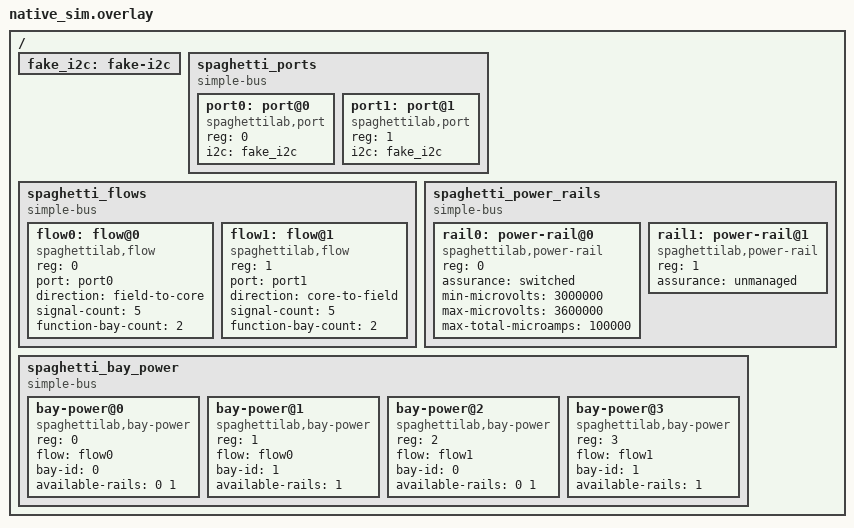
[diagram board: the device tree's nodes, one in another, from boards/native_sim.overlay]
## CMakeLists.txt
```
cmake_minimum_required(VERSION 3.20.0)

list(APPEND DTS_ROOT ${CMAKE_CURRENT_SOURCE_DIR}/../..)

find_package(Zephyr REQUIRED HINTS $ENV{ZEPHYR_BASE})
project(spaghetti_v1_extension_test)

target_sources(app PRIVATE
  src/main.c
  src/harness.c
  src/fake_temperature.c
  src/fake_button.c
  src/fake_pwm.c
  src/fake_rule.c
  src/fake_register_profiles.c
  src/fake_processing_block.c
  src/fake_eeprom_provider.c
  src/fake_analog_provider.c
  ../../subsys/schema/schema.c
  ../../subsys/driver_registry/driver_registry.c
  ../../subsys/rule_registry/rule_registry.c
  ../../subsys/block_registry/block_registry.c
  ../../subsys/device_profiles/device_profile.c
  ../../subsys/device_profiles/device_profile_exec.c
  ../../subsys/module_manager/module_manager.c
  ../../subsys/config/config.c
  ../../subsys/config/config_cbor.c
  ../../subsys/data/data.c
  ../../subsys/data/record_delivery.c
  ../../subsys/processing/processing.c
  ../../subsys/discovery/discovery.c
  ../../subsys/topology/topology.c
  ../../subsys/power/power.c
  ../../subsys/resources/resources_note_weak.c
  ../../spaghetti_modules/declarative_device/declarative_device.c
)

target_include_directories(app PRIVATE
  ../../include
  ../../subsys/driver_registry
  ../../subsys/rule_registry
  ../../subsys/block_registry
  ../../subsys/device_profiles
  ../../subsys/topology
  ../../subsys/power
  ../../subsys/discovery
  ../../spaghetti_modules/declarative_device
  src
)

zephyr_linker_sources(SECTIONS ../../subsys/driver_registry/driver_sections.ld)
zephyr_linker_sources(SECTIONS ../../subsys/rule_registry/rule_sections.ld)
zephyr_linker_sources(SECTIONS ../../subsys/block_registry/block_sections.ld)
zephyr_linker_sources(SECTIONS
  ../../subsys/device_profiles/device_profile_sections.ld)
zephyr_linker_sources(SECTIONS
  ../../subsys/discovery/discovery_sections.ld)
zephyr_linker_sources(SECTIONS
  ../../subsys/data/record_delivery_sections.ld)
zephyr_linker_sources(SECTIONS ../../subsys/core/health_sections.ld)
```

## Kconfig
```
mainmenu "Spaghetti V1 extension proof tests"

rsource "../../Kconfig.resources"

config SPAGHETTI_POWER
	bool
	default y

config SPAGHETTI_POWER_FAKE_BACKEND
	bool
	default y

config SPAGHETTI_POWER_LOG_LEVEL
	int
	default 0

config SPAGHETTI_TOPOLOGY_LOG_LEVEL
	int
	default 0

config SPAGHETTI_DRIVER_REGISTRY_LOG_LEVEL
	int
	default 0

config SPAGHETTI_RULE_REGISTRY_LOG_LEVEL
	int
	default 0

config SPAGHETTI_BLOCK_REGISTRY_LOG_LEVEL
	int
	default 0

config SPAGHETTI_DEVICE_PROFILE_LOG_LEVEL
	int
	default 0

config SPAGHETTI_SCHEMA_LOG_LEVEL
	int
	default 0

config SPAGHETTI_CONFIG_LOG_LEVEL
	int
	default 0

config SPAGHETTI_MODULE_MANAGER_LOG_LEVEL
	int
	default 0

config SPAGHETTI_DATA_LOG_LEVEL
	int
	default 0

config SPAGHETTI_RECORD_DELIVERY_LOG_LEVEL
	int
	default 0

config SPAGHETTI_PROCESSING_LOG_LEVEL
	int
	default 0

config SPAGHETTI_DISCOVERY_LOG_LEVEL
	int
	default 0

config SPAGHETTI_DISCOVERY_MAX_RESULTS
	int
	default 8

config SPAGHETTI_DECLARATIVE_DEVICE_MAX_INSTANCES
	int
	range 1 SPAGHETTI_MAX_MODULES
	default 4

config SPAGHETTI_DECLARATIVE_DEVICE_LOG_LEVEL
	int
	default 0

config SPAGHETTI_RUNTIME_STOP_TIMEOUT_MS
	int
	default 1000

config SPAGHETTI_MQTT_STOP_TIMEOUT_MS
	int
	default 2000

config SPAGHETTI_CONFIG_MIN_WRITE_INTERVAL_MS
	int
	default 0

config ZCBOR
	bool
	default y

source "Kconfig.zephyr"
```

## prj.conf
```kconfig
CONFIG_ZTEST=y
CONFIG_LOG=y
CONFIG_ZCBOR=y
CONFIG_ZBUS=y
CONFIG_ZBUS_MSG_SUBSCRIBER=y
CONFIG_ZBUS_PREFER_DYNAMIC_ALLOCATION=n
CONFIG_ZBUS_MSG_SUBSCRIBER_BUF_ALLOC_STATIC=y
CONFIG_ZBUS_MSG_SUBSCRIBER_NET_BUF_POOL_SIZE=8
CONFIG_ZBUS_MSG_SUBSCRIBER_NET_BUF_STATIC_DATA_SIZE=768
CONFIG_SPAGHETTI_RESOURCE_PROFILE_MINIMAL=y
```

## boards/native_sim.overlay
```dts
/ {
	fake_i2c: fake-i2c {
		status = "okay";
	};

	spaghetti_ports {
		compatible = "simple-bus";
		#address-cells = <1>;
		#size-cells = <0>;

		port0: port@0 {
			compatible = "spaghettilab,port";
			reg = <0>;
			i2c = <&fake_i2c>;
			status = "okay";
		};

		port1: port@1 {
			compatible = "spaghettilab,port";
			reg = <1>;
			i2c = <&fake_i2c>;
			status = "okay";
		};
	};

	spaghetti_flows {
		compatible = "simple-bus";
		#address-cells = <1>;
		#size-cells = <0>;

		flow0: flow@0 {
			compatible = "spaghettilab,flow";
			reg = <0>;
			port = <&port0>;
			direction = "field-to-core";
			signal-count = <5>;
			function-bay-count = <2>;
			status = "okay";
		};

		flow1: flow@1 {
			compatible = "spaghettilab,flow";
			reg = <1>;
			port = <&port1>;
			direction = "core-to-field";
			signal-count = <5>;
			function-bay-count = <2>;
			status = "okay";
		};
	};

	spaghetti_power_rails {
		compatible = "simple-bus";
		#address-cells = <1>;
		#size-cells = <0>;

		rail0: power-rail@0 {
			compatible = "spaghettilab,power-rail";
			reg = <0>;
			assurance = "switched";
			min-microvolts = <3000000>;
			max-microvolts = <3600000>;
			max-total-microamps = <100000>;
			status = "okay";
		};

		rail1: power-rail@1 {
			compatible = "spaghettilab,power-rail";
			reg = <1>;
			assurance = "unmanaged";
			status = "okay";
		};
	};

	spaghetti_bay_power {
		compatible = "simple-bus";
		#address-cells = <1>;
		#size-cells = <0>;

		bay-power@0 {
			compatible = "spaghettilab,bay-power";
			reg = <0>;
			flow = <&flow0>;
			bay-id = <0>;
			available-rails = <0 1>;
			status = "okay";
		};

		bay-power@1 {
			compatible = "spaghettilab,bay-power";
			reg = <1>;
			flow = <&flow0>;
			bay-id = <1>;
			available-rails = <1>;
			status = "okay";
		};

		bay-power@2 {
			compatible = "spaghettilab,bay-power";
			reg = <2>;
			flow = <&flow1>;
			bay-id = <0>;
			available-rails = <0 1>;
			status = "okay";
		};

		bay-power@3 {
			compatible = "spaghettilab,bay-power";
			reg = <3>;
			flow = <&flow1>;
			bay-id = <1>;
			available-rails = <1>;
			status = "okay";
		};
	};
};
```

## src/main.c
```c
/**
 * @file
 * @brief V1 extension proof: fake plug-ins only under tests/v1_extension/.
 *
 * Does not patch driver_registry/, rule_registry/, config/, data/, runtime/,
 * communication/, or services/mqtt/.
 */

#include <errno.h>
#include <stdbool.h>
#include <stdint.h>
#include <string.h>

#include <zephyr/sys/util.h>
#include <zephyr/ztest.h>

#include <spaghetti/block_registry.h>
#include <spaghetti/config.h>
#include <spaghetti/data.h>
#include <spaghetti/device_profile.h>
#include <spaghetti/discovery.h>
#include <spaghetti/driver_registry.h>
#include <spaghetti/module_manager.h>
#include <spaghetti/port.h>
#include <spaghetti/power.h>
#include <spaghetti/processing.h>
#include <spaghetti/record_delivery.h>
#include <spaghetti/rule_registry.h>
#include <spaghetti/schema.h>
#include <spaghetti/topology.h>

#include "harness.h"
#include "topology_internal.h"

int fake_button_inject_press(void);
uint64_t fake_pwm_last_duty_permille(void);
uint32_t fake_rule_last_actions_emitted(void);

SPAGHETTI_RECORD_CONSUMER_DEFINE(v1_mqtt_fake_consumer) = {
	.id = SPAGHETTI_RECORD_CONSUMER_ID_MQTT,
	.name = "mqtt_fake",
};

SPAGHETTI_RECORD_CONSUMER_DEFINE(v1_ble_fake_consumer) = {
	.id = SPAGHETTI_RECORD_CONSUMER_ID_BLE,
	.name = "ble_fake",
};

static void fill_temp(struct spaghetti_module_config *module,
		      spaghetti_module_key_t key, spaghetti_port_id_t port,
		      uint8_t address, spaghetti_bay_id_t bay,
		      spaghetti_power_rail_id_t rail)
{
	memset(module, 0, sizeof(*module));
	module->key = key;
	module->port_id = port;
	module->bay_id = bay;
	module->power_rail_id = rail;
	memcpy(module->type_id, "fake_temperature", sizeof("fake_temperature"));
	module->properties.field_count = 1U;
	module->properties.fields[0].field_id = 1U;
	module->properties.fields[0].type = SPAGHETTI_VALUE_UINT64;
	module->properties.fields[0].data.unsigned_integer = address;
}

static void fill_pwm(struct spaghetti_module_config *module,
		     spaghetti_module_key_t key, spaghetti_port_id_t port,
		     uint8_t line)
{
	memset(module, 0, sizeof(*module));
	module->key = key;
	module->port_id = port;
	module->bay_id = SPAGHETTI_BAY_ID_UNSPECIFIED;
	module->power_rail_id = SPAGHETTI_POWER_RAIL_UNSPECIFIED;
	memcpy(module->type_id, "fake_pwm", sizeof("fake_pwm"));
	module->properties.field_count = 1U;
	module->properties.fields[0].field_id = 1U;
	module->properties.fields[0].type = SPAGHETTI_VALUE_UINT64;
	module->properties.fields[0].data.unsigned_integer = line;
}

static void fill_button(struct spaghetti_module_config *module,
			spaghetti_module_key_t key, spaghetti_port_id_t port,
			uint8_t line)
{
	memset(module, 0, sizeof(*module));
	module->key = key;
	module->port_id = port;
	module->bay_id = SPAGHETTI_BAY_ID_UNSPECIFIED;
	module->power_rail_id = SPAGHETTI_POWER_RAIL_UNSPECIFIED;
	memcpy(module->type_id, "fake_button", sizeof("fake_button"));
	module->properties.field_count = 1U;
	module->properties.fields[0].field_id = 1U;
	module->properties.fields[0].type = SPAGHETTI_VALUE_UINT64;
	module->properties.fields[0].data.unsigned_integer = line;
}

static struct spaghetti_config make_platform_config(void)
{
	struct spaghetti_config config = {
		.version = SPAGHETTI_CONFIG_VERSION,
		.module_count = 3U,
		.schedule_count = 2U,
		.rule_count = 1U,
		.block_count = 1U,
		.edge_count = 1U,
		.schedules = {
			{ .enabled = true, .source_key = 10U, .period_ms = 100U },
			{ .enabled = true, .source_key = 11U, .period_ms = 200U },
		},
		.connectivity_policy = SPAGHETTI_CONNECTIVITY_ONLINE,
		.energy_policy = {
			.ble_availability = SPAGHETTI_BLE_OFF,
		},
	};

	/* Two I2C modules on the same Port; one bay known, one unspecified. */
	fill_temp(&config.modules[0], 10U, 0U, 0x48U, 0U, 0U);
	fill_temp(&config.modules[1], 11U, 0U, 0x49U,
		  SPAGHETTI_BAY_ID_UNSPECIFIED, SPAGHETTI_POWER_RAIL_UNSPECIFIED);
	fill_pwm(&config.modules[2], 20U, 1U, 0U);

	memcpy(config.rules[0].type_id, "fake_rule", sizeof("fake_rule"));
	config.rules[0].key = 30U;
	config.rules[0].properties.field_count = 4U;
	config.rules[0].properties.fields[0] = (struct spaghetti_value){
		.field_id = 1U,
		.type = SPAGHETTI_VALUE_UINT64,
		.data.unsigned_integer = 10U,
	};
	config.rules[0].properties.fields[1] = (struct spaghetti_value){
		.field_id = 2U,
		.type = SPAGHETTI_VALUE_UINT64,
		.data.unsigned_integer = 1U,
	};
	config.rules[0].properties.fields[2] = (struct spaghetti_value){
		.field_id = 3U,
		.type = SPAGHETTI_VALUE_UINT64,
		.data.unsigned_integer = 20U,
	};
	config.rules[0].properties.fields[3] = (struct spaghetti_value){
		.field_id = 4U,
		.type = SPAGHETTI_VALUE_INT64,
		.data.signed_integer = 20000,
	};

	config.blocks[0].key = 40U;
	memcpy(config.blocks[0].type_id, "fake_processing_block",
	       sizeof("fake_processing_block"));
	config.blocks[0].min_version = 1U;
	config.edges[0] = (struct spaghetti_edge_config){
		.source_key = 10U,
		.source_port_or_field = 1U,
		.target_key = 40U,
		.target_input = 0U,
		.source_kind = SPAGHETTI_EDGE_SOURCE_MODULE,
	};

	return config;
}

static void *v1_setup(void)
{
	const struct spaghetti_config empty = {
		.version = SPAGHETTI_CONFIG_VERSION,
		.connectivity_policy = SPAGHETTI_CONNECTIVITY_ONLINE,
		.energy_policy = {
			.ble_availability = SPAGHETTI_BLE_OFF,
		},
	};

	v1_harness_reset();
	v1_port_reset();
	spaghetti_topology_reset();
	zassert_ok(spaghetti_topology_init());
	zassert_ok(spaghetti_power_init());
	zassert_ok(spaghetti_driver_registry_init());
	zassert_ok(spaghetti_rule_registry_init());
	zassert_ok(spaghetti_block_registry_init());
	zassert_ok(spaghetti_device_profile_init());
	zassert_ok(spaghetti_module_manager_init());
	zassert_ok(spaghetti_processing_init());
	zassert_ok(spaghetti_data_init());
	zassert_ok(spaghetti_record_delivery_init(1U));
	zassert_ok(spaghetti_discovery_init());
	zassert_ok(spaghetti_config_init(&empty));
	return NULL;
}

static void v1_before(void *fixture)
{
	struct spaghetti_config empty = {
		.version = SPAGHETTI_CONFIG_VERSION,
		.connectivity_policy = SPAGHETTI_CONNECTIVITY_ONLINE,
		.energy_policy = {
			.ble_availability = SPAGHETTI_BLE_OFF,
		},
	};
	struct spaghetti_config snapshot;
	struct spaghetti_config_revision revision;
	struct spaghetti_config_commit_result result;

	ARG_UNUSED(fixture);
	v1_harness_reset();
	zassert_ok(spaghetti_config_get_snapshot(&snapshot, &revision));
	zassert_ok(spaghetti_config_apply(&empty, revision.generation, &result));
	v1_port_reset();
	(void)spaghetti_record_delivery_init(k_uptime_get() + 1);
}

ZTEST(v1_extension, test_plugins_register_without_central_patches)
{
	zassert_not_null(spaghetti_driver_registry_find("fake_temperature"));
	zassert_not_null(spaghetti_driver_registry_find("fake_button"));
	zassert_not_null(spaghetti_driver_registry_find("fake_pwm"));
	zassert_not_null(spaghetti_driver_registry_find("declarative-device"));
	zassert_not_null(spaghetti_rule_registry_find("fake_rule"));
	zassert_not_null(spaghetti_block_registry_find("fake_processing_block"));
	zassert_not_null(spaghetti_device_profile_find("fake-register-a", 1U,
						       NULL));
	zassert_not_null(spaghetti_device_profile_find("fake-register-b", 1U,
						       NULL));
	zassert_true(spaghetti_driver_registry_count() >= 4U);
}

ZTEST(v1_extension, test_two_flows_rails_and_power_admission)
{
	const struct spaghetti_flow_descriptor *flow0;
	const struct spaghetti_flow_descriptor *flow1;
	const struct spaghetti_power_binding controlled = {
		.flow_id = 0U,
		.bay_id = 0U,
		.rail_id = 0U,
	};
	const struct spaghetti_power_binding passive = {
		.flow_id = 0U,
		.bay_id = 1U,
		.rail_id = 1U,
	};
	const struct spaghetti_module_power_requirement need = {
		.declared = true,
		.min_microvolts = 3000000U,
		.max_microvolts = 3600000U,
		.max_microamps = 10000U,
	};
	enum spaghetti_power_admission_state admission;

	zassert_equal(spaghetti_topology_flow_count(), 2U);
	flow0 = spaghetti_topology_flow_get(0U);
	flow1 = spaghetti_topology_flow_get(1U);
	zassert_not_null(flow0);
	zassert_not_null(flow1);
	zassert_equal(flow0->signal_count, SPAGHETTI_FLOW_SIGNAL_COUNT);
	zassert_equal(flow1->signal_count, SPAGHETTI_FLOW_SIGNAL_COUNT);

	zassert_ok(spaghetti_power_validate_binding(&controlled, &need,
						    &admission));
	zassert_equal(admission, SPAGHETTI_POWER_ADMISSION_ENFORCED);

	zassert_ok(spaghetti_power_validate_binding(&passive, &need,
						    &admission));
	zassert_equal(admission, SPAGHETTI_POWER_ADMISSION_UNVERIFIED);
}

ZTEST(v1_extension, test_config_apply_schedules_rule_graph_rollback)
{
	struct spaghetti_config candidate = make_platform_config();
	struct spaghetti_config snapshot;
	struct spaghetti_config_revision revision;
	struct spaghetti_config_commit_result result;
	struct spaghetti_module_snapshot mod;
	struct v1_harness *h = v1_harness_get();
	uint32_t writes_before;

	zassert_ok(spaghetti_config_get_snapshot(&snapshot, &revision));
	writes_before = h->storage_writes;
	zassert_ok(spaghetti_config_apply(&candidate, revision.generation,
					  &result));
	zassert_true(result.changed);
	zassert_equal(h->storage_writes, writes_before + 1U);
	zassert_equal(h->runtime_schedule_count, 2U);
	zassert_equal(h->runtime_rule_count, 1U);
	zassert_ok(spaghetti_module_manager_get_by_key(10U, &mod));
	zassert_ok(spaghetti_module_manager_get_by_key(11U, &mod));
	zassert_ok(spaghetti_module_manager_get_by_key(20U, &mod));

	/* Identical apply is a no-op (no generation bump / storage write). */
	zassert_ok(spaghetti_config_get_snapshot(&snapshot, &revision));
	writes_before = h->storage_writes;
	zassert_ok(spaghetti_config_apply(&snapshot, revision.generation,
					  &result));
	zassert_false(result.changed);
	zassert_equal(h->storage_writes, writes_before);

	/* Empty Config rolls back modules. */
	{
		struct spaghetti_config empty = {
			.version = SPAGHETTI_CONFIG_VERSION,
			.connectivity_policy = SPAGHETTI_CONNECTIVITY_ONLINE,
			.energy_policy = {
				.ble_availability = SPAGHETTI_BLE_OFF,
			},
		};

		zassert_ok(spaghetti_config_get_snapshot(&snapshot, &revision));
		zassert_ok(spaghetti_config_apply(&empty, revision.generation,
						  &result));
		zassert_equal(spaghetti_module_manager_get_by_key(10U, &mod),
			      -ENOENT);
		zassert_equal(spaghetti_module_manager_get_by_key(11U, &mod),
			      -ENOENT);
		zassert_equal(spaghetti_module_manager_get_by_key(20U, &mod),
			      -ENOENT);
	}
}

static int button_capture(const struct spaghetti_record_payload *payload,
			  void *user_data)
{
	int *count = user_data;

	ARG_UNUSED(payload);
	if (count != NULL) {
		++(*count);
	}
	return 0;
}

ZTEST(v1_extension, test_temperature_pwm_data_and_consumers)
{
	struct spaghetti_config candidate = make_platform_config();
	struct spaghetti_config_revision revision;
	struct spaghetti_config_commit_result result;
	struct spaghetti_config snapshot;
	struct spaghetti_module_snapshot mod;
	struct spaghetti_record record;
	struct spaghetti_record_cursor cursor;
	struct spaghetti_module_command command;

	zassert_ok(spaghetti_config_get_snapshot(&snapshot, &revision));
	zassert_ok(spaghetti_config_apply(&candidate, revision.generation,
					  &result));

	zassert_ok(spaghetti_module_manager_get_by_key(10U, &mod));
	zassert_ok(spaghetti_module_manager_read(mod.id, &record));
	zassert_equal(record.payload.values.fields[0].type,
		      SPAGHETTI_VALUE_INT64);

	zassert_ok(spaghetti_module_manager_get_by_key(20U, &mod));
	memset(&command, 0, sizeof(command));
	command.command_id = 1U;
	command.arguments.field_count = 1U;
	command.arguments.fields[0] = (struct spaghetti_value){
		.field_id = 1U,
		.type = SPAGHETTI_VALUE_UINT64,
		.data.unsigned_integer = 250U,
	};
	zassert_ok(spaghetti_module_manager_command(mod.id, &command));
	zassert_equal(fake_pwm_last_duty_permille(), 250U);

	record.boot_id = 1U;
	record.timestamp_ms = 1;
	record.sequence = 1U;
	zassert_ok(spaghetti_record_delivery_set_consumer_active(
		SPAGHETTI_RECORD_CONSUMER_ID_MQTT, true));
	zassert_ok(spaghetti_record_delivery_set_consumer_active(
		SPAGHETTI_RECORD_CONSUMER_ID_BLE, true));
	zassert_ok(spaghetti_data_publish(&record, K_NO_WAIT));

	zassert_ok(spaghetti_record_delivery_peek(
		SPAGHETTI_RECORD_CONSUMER_ID_MQTT, &record, &cursor));
	zassert_ok(spaghetti_record_delivery_ack(
		SPAGHETTI_RECORD_CONSUMER_ID_MQTT, &cursor));
	/* BLE cursor is independent — still pending after MQTT ACK. */
	zassert_ok(spaghetti_record_delivery_peek(
		SPAGHETTI_RECORD_CONSUMER_ID_BLE, &record, &cursor));
	zassert_equal(record.sequence, 1U);
	zassert_ok(spaghetti_record_delivery_ack(
		SPAGHETTI_RECORD_CONSUMER_ID_BLE, &cursor));
}

ZTEST(v1_extension, test_button_event_and_i2c_owners_transport_reject)
{
	struct spaghetti_config config = {
		.version = SPAGHETTI_CONFIG_VERSION,
		.module_count = 2U,
		.connectivity_policy = SPAGHETTI_CONNECTIVITY_ONLINE,
		.energy_policy = {
			.ble_availability = SPAGHETTI_BLE_OFF,
		},
	};
	struct spaghetti_config_revision revision;
	struct spaghetti_config_commit_result result;
	struct spaghetti_config snapshot;
	struct spaghetti_module_snapshot mod;
	const struct spaghetti_port *port0 = spaghetti_port_get(0U);
	enum spaghetti_port_transport transport;
	size_t owners;
	int events = 0;

	fill_temp(&config.modules[0], 10U, 0U, 0x48U,
		  SPAGHETTI_BAY_ID_UNSPECIFIED, SPAGHETTI_POWER_RAIL_UNSPECIFIED);
	fill_temp(&config.modules[1], 11U, 0U, 0x49U,
		  SPAGHETTI_BAY_ID_UNSPECIFIED, SPAGHETTI_POWER_RAIL_UNSPECIFIED);

	zassert_ok(spaghetti_config_get_snapshot(&snapshot, &revision));
	zassert_ok(spaghetti_config_apply(&config, revision.generation,
					  &result));
	zassert_ok(spaghetti_port_get_active_transport(port0, &transport,
						       &owners));
	zassert_equal(transport, SPAGHETTI_PORT_TRANSPORT_I2C);
	zassert_equal(owners, 2U);

	/* Incompatible transport while I2C is active must be rejected. */
	zassert_equal(spaghetti_port_acquire(port0, 99U,
					     SPAGHETTI_PORT_TRANSPORT_UART),
		      -EBUSY);

	/* Button on Port 1. */
	{
		struct spaghetti_config button = {
			.version = SPAGHETTI_CONFIG_VERSION,
			.module_count = 1U,
			.connectivity_policy = SPAGHETTI_CONNECTIVITY_ONLINE,
			.energy_policy = {
				.ble_availability = SPAGHETTI_BLE_OFF,
			},
		};

		fill_button(&button.modules[0], 21U, 1U, 2U);
		zassert_ok(spaghetti_config_get_snapshot(&snapshot, &revision));
		zassert_ok(spaghetti_config_apply(&button, revision.generation,
						  &result));
		zassert_ok(spaghetti_module_manager_get_by_key(21U, &mod));
		zassert_ok(spaghetti_module_manager_start_events(
			mod.id, button_capture, &events));
		zassert_ok(fake_button_inject_press());
		zassert_equal(events, 1);
		zassert_ok(spaghetti_module_manager_stop_events(mod.id));
	}
}

ZTEST(v1_extension, test_discovery_profiles_and_catalog)
{
	struct spaghetti_discovery_scan_policy policy = {
		.allow_read_only = true,
		.allow_state_changing = false,
		.timeout_per_provider = K_MSEC(10),
	};
	struct spaghetti_discovery_candidate listed[8];
	size_t count = 0U;
	bool saw_eeprom = false;
	bool saw_analog = false;
	bool saw_temp = false;
	bool saw_decl = false;

	zassert_ok(spaghetti_discovery_scan_port(0U, &policy));
	zassert_ok(spaghetti_discovery_list(listed, ARRAY_SIZE(listed), &count));
	zassert_true(count >= 2U);
	for (size_t idx = 0U; idx < count; ++idx) {
		if (listed[idx].confidence ==
		    SPAGHETTI_DISCOVERY_AUTHORITATIVE) {
			saw_eeprom = true;
		}
		if (listed[idx].confidence == SPAGHETTI_DISCOVERY_HEURISTIC) {
			saw_analog = true;
		}
	}
	zassert_true(saw_eeprom);
	zassert_true(saw_analog);

	for (size_t idx = 0U; idx < spaghetti_driver_registry_count(); ++idx) {
		const struct spaghetti_module_driver *driver =
			spaghetti_driver_registry_get(idx);

		if (strcmp(driver->type_id, "fake_temperature") == 0) {
			saw_temp = true;
		}
		if (strcmp(driver->type_id, "declarative-device") == 0) {
			saw_decl = true;
		}
	}
	zassert_true(saw_temp);
	zassert_true(saw_decl);
	zassert_not_null(spaghetti_device_profile_find("fake-register-a", 1U,
						       NULL));
	zassert_not_null(spaghetti_device_profile_find("fake-register-b", 1U,
						       NULL));
}

ZTEST_SUITE(v1_extension, NULL, v1_setup, v1_before, NULL, NULL);
```

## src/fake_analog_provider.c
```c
/**
 * @file
 * @brief Heuristic analog Discovery provider (fake).
 */

#include "harness.h"

#include <errno.h>
#include <string.h>

#include <zephyr/kernel.h>

#include <spaghetti/discovery.h>
#include <spaghetti/port.h>
#include <spaghetti/power.h>
#include <spaghetti/topology.h>

static int fake_analog_scan(const struct spaghetti_port *port,
			    spaghetti_discovery_emit_candidate_cb_t emit,
			    void *emit_user_data, k_timeout_t timeout)
{
	struct v1_harness *h = v1_harness_get();
	struct spaghetti_discovery_candidate candidate;

	ARG_UNUSED(port);
	ARG_UNUSED(timeout);

	if (!h->analog_enabled || (h->analog_identity_size == 0U)) {
		return 0;
	}

	memset(&candidate, 0, sizeof(candidate));
	candidate.bay_id = SPAGHETTI_BAY_ID_UNSPECIFIED;
	candidate.power_rail_id = SPAGHETTI_POWER_RAIL_UNSPECIFIED;
	candidate.identity_size = (uint8_t)h->analog_identity_size;
	memcpy(candidate.identity, h->analog_identity, h->analog_identity_size);
	strncpy(candidate.suggested_type_id, "fake_temperature",
		sizeof(candidate.suggested_type_id) - 1U);
	candidate.suggested_properties.field_count = 1U;
	candidate.suggested_properties.fields[0] = (struct spaghetti_value){
		.field_id = 1U,
		.type = SPAGHETTI_VALUE_UINT64,
		.data.unsigned_integer = 1200U,
	};
	return emit(&candidate, emit_user_data);
}

static const struct spaghetti_discovery_provider_ops ops = {
	.scan = fake_analog_scan,
};

SPAGHETTI_DISCOVERY_PROVIDER_DEFINE(fake_analog_provider) = {
	.provider_id = "v1.fake_analog",
	.api_version = SPAGHETTI_DISCOVERY_PROVIDER_API_VERSION,
	.method = SPAGHETTI_DISCOVERY_METHOD_ANALOG,
	.confidence = SPAGHETTI_DISCOVERY_HEURISTIC,
	.probe_flags = SPAGHETTI_DISCOVERY_PROBE_READ_ONLY,
	.required_capabilities = SPAGHETTI_PORT_CAP_ADC,
	.ops = &ops,
};
```

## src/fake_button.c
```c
/**
 * @file
 * @brief Fake button Module: GPIO config, BOOL event, async start/stop.
 */

#include <errno.h>
#include <stdbool.h>
#include <string.h>

#include <zephyr/sys/util.h>

#include <spaghetti/module_driver.h>
#include <spaghetti/port.h>
#include <spaghetti/schema.h>

enum {
	FAKE_BUTTON_CFG_LINE = 1U,
	FAKE_BUTTON_FIELD_PRESSED = 1U,
};

struct fake_button_context {
	bool used;
	uint8_t line;
	spaghetti_module_event_cb_t emit;
	void *emit_user_data;
	bool armed;
};

static struct fake_button_context contexts[CONFIG_SPAGHETTI_MAX_MODULES];
static struct fake_button_context *last_armed;

static const struct spaghetti_field_descriptor config_fields[] = {
	{
		.field_id = FAKE_BUTTON_CFG_LINE,
		.type = SPAGHETTI_VALUE_UINT64,
		.flags = SPAGHETTI_FIELD_REQUIRED | SPAGHETTI_FIELD_WRITABLE,
		.unsigned_minimum = 0U,
		.unsigned_maximum = 4U,
		.name = "line",
		.description = "Connector signal index",
		.unit = "",
	},
};

static const struct spaghetti_schema_descriptor config_schema = {
	.schema_id = "spaghetti.fake_button.config",
	.version = 1U,
	.fields = config_fields,
	.field_count = ARRAY_SIZE(config_fields),
};

static const struct spaghetti_field_descriptor event_fields[] = {
	{
		.field_id = FAKE_BUTTON_FIELD_PRESSED,
		.type = SPAGHETTI_VALUE_BOOL,
		.flags = SPAGHETTI_FIELD_REQUIRED,
		.name = "pressed",
		.description = "Button pressed event",
		.unit = "",
	},
};

static const struct spaghetti_schema_descriptor event_schema = {
	.schema_id = "spaghetti.fake_button.event",
	.version = 1U,
	.fields = event_fields,
	.field_count = ARRAY_SIZE(event_fields),
};

static const struct spaghetti_schema_descriptor *const record_schemas[] = {
	&event_schema,
};

static int validate_config(const struct spaghetti_property_set *config)
{
	return spaghetti_property_validate(config, &config_schema);
}

static int describe_endpoint(const struct spaghetti_property_set *config,
			     struct spaghetti_module_endpoint *out)
{
	const struct spaghetti_value *line;

	if (out == NULL) {
		return -EINVAL;
	}
	line = spaghetti_property_find(config, FAKE_BUTTON_CFG_LINE);
	if ((line == NULL) || (line->type != SPAGHETTI_VALUE_UINT64)) {
		return -EINVAL;
	}
	*out = (struct spaghetti_module_endpoint){
		.kind = SPAGHETTI_ENDPOINT_GPIO_LINE,
		.value_size = 1U,
		.value = {(uint8_t)line->data.unsigned_integer},
	};
	return 0;
}

static int init_module(struct spaghetti_module *module,
		       const struct spaghetti_property_set *config)
{
	const struct spaghetti_value *line =
		spaghetti_property_find(config, FAKE_BUTTON_CFG_LINE);

	if ((module == NULL) || (module->context != NULL) || (line == NULL)) {
		return -EINVAL;
	}
	for (size_t idx = 0U; idx < ARRAY_SIZE(contexts); ++idx) {
		if (!contexts[idx].used) {
			memset(&contexts[idx], 0, sizeof(contexts[idx]));
			contexts[idx].used = true;
			contexts[idx].line =
				(uint8_t)line->data.unsigned_integer;
			module->context = &contexts[idx];
			return 0;
		}
	}
	return -ENOMEM;
}

static int start_module(struct spaghetti_module *module,
			spaghetti_module_event_cb_t emit,
			void *emit_user_data)
{
	struct fake_button_context *ctx;

	if ((module == NULL) || (module->context == NULL) || (emit == NULL)) {
		return -EINVAL;
	}
	ctx = module->context;
	ctx->emit = emit;
	ctx->emit_user_data = emit_user_data;
	ctx->armed = true;
	last_armed = ctx;
	return 0;
}

static int read_module(struct spaghetti_module *module,
		       struct spaghetti_record_payload *out)
{
	if ((module == NULL) || (module->context == NULL) || (out == NULL)) {
		return -EINVAL;
	}
	memset(out, 0, sizeof(*out));
	out->kind = SPAGHETTI_RECORD_EVENT;
	out->schema_version = 1U;
	strncpy(out->schema_id, event_schema.schema_id,
		sizeof(out->schema_id) - 1U);
	out->values.field_count = 1U;
	out->values.fields[0] = (struct spaghetti_value){
		.field_id = FAKE_BUTTON_FIELD_PRESSED,
		.type = SPAGHETTI_VALUE_BOOL,
		.data.boolean = false,
	};
	return 0;
}

static int stop_module(struct spaghetti_module *module)
{
	struct fake_button_context *ctx;

	if ((module == NULL) || (module->context == NULL)) {
		return -EINVAL;
	}
	ctx = module->context;
	ctx->armed = false;
	ctx->emit = NULL;
	ctx->emit_user_data = NULL;
	if (last_armed == ctx) {
		last_armed = NULL;
	}
	return 0;
}

static int deinit_module(struct spaghetti_module *module)
{
	struct fake_button_context *ctx;

	if ((module == NULL) || (module->context == NULL)) {
		return -EINVAL;
	}
	(void)stop_module(module);
	ctx = module->context;
	ctx->used = false;
	module->context = NULL;
	return 0;
}

int fake_button_inject_press(void)
{
	struct spaghetti_record_payload payload;

	if ((last_armed == NULL) || !last_armed->armed ||
	    (last_armed->emit == NULL)) {
		return -ENOENT;
	}
	memset(&payload, 0, sizeof(payload));
	payload.kind = SPAGHETTI_RECORD_EVENT;
	payload.schema_version = 1U;
	strncpy(payload.schema_id, event_schema.schema_id,
		sizeof(payload.schema_id) - 1U);
	payload.values.field_count = 1U;
	payload.values.fields[0] = (struct spaghetti_value){
		.field_id = FAKE_BUTTON_FIELD_PRESSED,
		.type = SPAGHETTI_VALUE_BOOL,
		.data.boolean = true,
	};
	return last_armed->emit(&payload, last_armed->emit_user_data);
}

static const struct spaghetti_module_driver_ops ops = {
	.validate_config = validate_config,
	.describe_endpoint = describe_endpoint,
	.init = init_module,
	.read = read_module,
	.start = start_module,
	.stop = stop_module,
	.deinit = deinit_module,
};

SPAGHETTI_MODULE_DRIVER_DEFINE(spaghetti_fake_button_driver) = {
	.type_id = "fake_button",
	.api_version = SPAGHETTI_MODULE_DRIVER_API_VERSION,
	.required_capabilities = SPAGHETTI_PORT_CAP_DIGITAL_INPUT,
	.transport = SPAGHETTI_PORT_TRANSPORT_GPIO,
	.power_requirement = { .declared = false },
	.config_schema = &config_schema,
	.record_schemas = record_schemas,
	.record_schema_count = ARRAY_SIZE(record_schemas),
	.ops = &ops,
};
```

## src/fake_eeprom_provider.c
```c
/**
 * @file
 * @brief Authoritative EEPROM Discovery provider (fake).
 */

#include "harness.h"

#include <errno.h>
#include <string.h>

#include <zephyr/kernel.h>

#include <spaghetti/discovery.h>
#include <spaghetti/port.h>
#include <spaghetti/power.h>
#include <spaghetti/topology.h>

static int fake_eeprom_scan(const struct spaghetti_port *port,
			    spaghetti_discovery_emit_candidate_cb_t emit,
			    void *emit_user_data, k_timeout_t timeout)
{
	struct v1_harness *h = v1_harness_get();
	struct spaghetti_discovery_candidate candidate;

	ARG_UNUSED(port);
	ARG_UNUSED(timeout);

	if (!h->eeprom_enabled || (h->eeprom_identity_size == 0U)) {
		return 0;
	}

	memset(&candidate, 0, sizeof(candidate));
	candidate.bay_id = SPAGHETTI_BAY_ID_UNSPECIFIED;
	candidate.power_rail_id = SPAGHETTI_POWER_RAIL_UNSPECIFIED;
	candidate.identity_size = (uint8_t)h->eeprom_identity_size;
	memcpy(candidate.identity, h->eeprom_identity, h->eeprom_identity_size);
	strncpy(candidate.suggested_type_id, "fake_temperature",
		sizeof(candidate.suggested_type_id) - 1U);
	return emit(&candidate, emit_user_data);
}

static const struct spaghetti_discovery_provider_ops ops = {
	.scan = fake_eeprom_scan,
};

SPAGHETTI_DISCOVERY_PROVIDER_DEFINE(fake_eeprom_provider) = {
	.provider_id = "v1.fake_eeprom",
	.api_version = SPAGHETTI_DISCOVERY_PROVIDER_API_VERSION,
	.method = SPAGHETTI_DISCOVERY_METHOD_EEPROM,
	.confidence = SPAGHETTI_DISCOVERY_AUTHORITATIVE,
	.probe_flags = SPAGHETTI_DISCOVERY_PROBE_READ_ONLY,
	.required_capabilities = SPAGHETTI_PORT_CAP_I2C,
	.ops = &ops,
};
```

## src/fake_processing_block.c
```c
/**
 * @file
 * @brief Fake processing block with bounded state (running sum).
 */

#include <errno.h>
#include <stdbool.h>
#include <stdint.h>
#include <string.h>

#include <zephyr/sys/util.h>

#include <spaghetti/block_driver.h>
#include <spaghetti/schema.h>

struct fake_block_state {
	int64_t sum;
	uint32_t count;
};

static const struct spaghetti_field_descriptor config_fields[1];
static const struct spaghetti_schema_descriptor config_schema = {
	.schema_id = "spaghetti.fake_proc.config",
	.version = 1U,
	.fields = config_fields,
	.field_count = 0U,
};

static const struct spaghetti_block_port_descriptor inputs[] = {
	{
		.port_id = 0U,
		.name = "in",
		.accepted_types = SPAGHETTI_BLOCK_TYPE_INT64,
		.required = true,
	},
};

static const struct spaghetti_block_port_descriptor outputs[] = {
	{
		.port_id = 0U,
		.name = "sum",
		.accepted_types = SPAGHETTI_BLOCK_TYPE_INT64,
		.required = false,
	},
};

static int validate(const struct spaghetti_property_set *config)
{
	ARG_UNUSED(config);
	return 0;
}

static int init_block(const struct spaghetti_property_set *config, void *state)
{
	struct fake_block_state *ctx = state;

	ARG_UNUSED(config);
	if (ctx == NULL) {
		return -EINVAL;
	}
	ctx->sum = 0;
	ctx->count = 0U;
	return 0;
}

static int process_block(void *state, void *workspace,
			 const struct spaghetti_value *inputs_v,
			 const bool *input_valid, size_t input_count,
			 struct spaghetti_value *outputs_v, bool *output_valid,
			 size_t output_count,
			 const struct spaghetti_record *source_record,
			 spaghetti_block_publish_cb_t publish,
			 void *publish_user_data)
{
	struct fake_block_state *ctx = state;

	ARG_UNUSED(workspace);
	ARG_UNUSED(source_record);
	ARG_UNUSED(publish);
	ARG_UNUSED(publish_user_data);

	if ((ctx == NULL) || (input_count < 1U) || !input_valid[0] ||
	    (output_count < 1U)) {
		return -EINVAL;
	}
	ctx->sum += inputs_v[0].data.signed_integer;
	++ctx->count;
	outputs_v[0].field_id = 0U;
	outputs_v[0].type = SPAGHETTI_VALUE_INT64;
	outputs_v[0].data.signed_integer = ctx->sum;
	output_valid[0] = true;
	return 0;
}

static void reset_block(void *state)
{
	struct fake_block_state *ctx = state;

	if (ctx != NULL) {
		ctx->sum = 0;
		ctx->count = 0U;
	}
}

static void deinit_block(void *state)
{
	reset_block(state);
}

static const struct spaghetti_block_driver_ops ops = {
	.validate = validate,
	.init = init_block,
	.process = process_block,
	.reset = reset_block,
	.deinit = deinit_block,
};

SPAGHETTI_BLOCK_DRIVER_DEFINE(spaghetti_fake_processing_block) = {
	.type_id = "fake_processing_block",
	.api_version = SPAGHETTI_BLOCK_DRIVER_API_VERSION,
	.algorithm_version = 1U,
	.config_schema = &config_schema,
	.inputs = inputs,
	.input_count = ARRAY_SIZE(inputs),
	.outputs = outputs,
	.output_count = ARRAY_SIZE(outputs),
	.state_size = sizeof(struct fake_block_state),
	.state_align = __alignof__(struct fake_block_state),
	.workspace_size = 0U,
	.max_cost_per_record = 1U,
	.required_capabilities = 0U,
	.ops = &ops,
};
```

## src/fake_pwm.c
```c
/**
 * @file
 * @brief Fake PWM Module: output config, UINT64 duty permille command.
 */

#include <errno.h>
#include <stdbool.h>
#include <string.h>

#include <zephyr/sys/util.h>

#include <spaghetti/module_driver.h>
#include <spaghetti/port.h>
#include <spaghetti/schema.h>

enum {
	FAKE_PWM_CFG_LINE = 1U,
	FAKE_PWM_CMD_SET_DUTY = 1U,
	FAKE_PWM_CMD_FIELD_DUTY = 1U,
};

struct fake_pwm_context {
	bool used;
	uint8_t line;
	uint64_t duty_permille;
};

static struct fake_pwm_context contexts[CONFIG_SPAGHETTI_MAX_MODULES];
static uint64_t last_duty_permille;

static const struct spaghetti_field_descriptor config_fields[] = {
	{
		.field_id = FAKE_PWM_CFG_LINE,
		.type = SPAGHETTI_VALUE_UINT64,
		.flags = SPAGHETTI_FIELD_REQUIRED | SPAGHETTI_FIELD_WRITABLE,
		.unsigned_minimum = 0U,
		.unsigned_maximum = 4U,
		.name = "line",
		.description = "PWM connector signal",
		.unit = "",
	},
};

static const struct spaghetti_schema_descriptor config_schema = {
	.schema_id = "spaghetti.fake_pwm.config",
	.version = 1U,
	.fields = config_fields,
	.field_count = ARRAY_SIZE(config_fields),
};

static const struct spaghetti_field_descriptor duty_fields[] = {
	{
		.field_id = FAKE_PWM_CMD_FIELD_DUTY,
		.type = SPAGHETTI_VALUE_UINT64,
		.flags = SPAGHETTI_FIELD_REQUIRED,
		.unsigned_minimum = 0U,
		.unsigned_maximum = 1000U,
		.name = "duty_permille",
		.description = "Duty cycle in permille",
		.unit = "permille",
	},
};

static const struct spaghetti_schema_descriptor duty_schema = {
	.schema_id = "spaghetti.fake_pwm.set_duty",
	.version = 1U,
	.fields = duty_fields,
	.field_count = ARRAY_SIZE(duty_fields),
};

static const struct spaghetti_command_descriptor commands[] = {
	{
		.command_id = FAKE_PWM_CMD_SET_DUTY,
		.name = "set_duty",
		.argument_schema = &duty_schema,
	},
};

static int validate_config(const struct spaghetti_property_set *config)
{
	return spaghetti_property_validate(config, &config_schema);
}

static int describe_endpoint(const struct spaghetti_property_set *config,
			     struct spaghetti_module_endpoint *out)
{
	const struct spaghetti_value *line;

	if (out == NULL) {
		return -EINVAL;
	}
	line = spaghetti_property_find(config, FAKE_PWM_CFG_LINE);
	if ((line == NULL) || (line->type != SPAGHETTI_VALUE_UINT64)) {
		return -EINVAL;
	}
	*out = (struct spaghetti_module_endpoint){
		.kind = SPAGHETTI_ENDPOINT_GPIO_LINE,
		.value_size = 1U,
		.value = {(uint8_t)line->data.unsigned_integer},
	};
	return 0;
}

static int init_module(struct spaghetti_module *module,
		       const struct spaghetti_property_set *config)
{
	const struct spaghetti_value *line =
		spaghetti_property_find(config, FAKE_PWM_CFG_LINE);

	if ((module == NULL) || (module->context != NULL) || (line == NULL)) {
		return -EINVAL;
	}
	for (size_t idx = 0U; idx < ARRAY_SIZE(contexts); ++idx) {
		if (!contexts[idx].used) {
			memset(&contexts[idx], 0, sizeof(contexts[idx]));
			contexts[idx].used = true;
			contexts[idx].line =
				(uint8_t)line->data.unsigned_integer;
			module->context = &contexts[idx];
			return 0;
		}
	}
	return -ENOMEM;
}

static int command_module(struct spaghetti_module *module,
			  const struct spaghetti_module_command *command)
{
	struct fake_pwm_context *ctx;
	const struct spaghetti_value *duty;

	if ((module == NULL) || (module->context == NULL) || (command == NULL)) {
		return -EINVAL;
	}
	if (command->command_id != FAKE_PWM_CMD_SET_DUTY) {
		return -ENOTSUP;
	}
	duty = spaghetti_property_find(&command->arguments,
				       FAKE_PWM_CMD_FIELD_DUTY);
	if ((duty == NULL) || (duty->type != SPAGHETTI_VALUE_UINT64) ||
	    (duty->data.unsigned_integer > 1000U)) {
		return -EINVAL;
	}
	ctx = module->context;
	ctx->duty_permille = duty->data.unsigned_integer;
	last_duty_permille = ctx->duty_permille;
	return 0;
}

static int deinit_module(struct spaghetti_module *module)
{
	struct fake_pwm_context *ctx;

	if ((module == NULL) || (module->context == NULL)) {
		return -EINVAL;
	}
	ctx = module->context;
	ctx->used = false;
	module->context = NULL;
	return 0;
}

uint64_t fake_pwm_last_duty_permille(void)
{
	return last_duty_permille;
}

static const struct spaghetti_module_driver_ops ops = {
	.validate_config = validate_config,
	.describe_endpoint = describe_endpoint,
	.init = init_module,
	.command = command_module,
	.deinit = deinit_module,
};

SPAGHETTI_MODULE_DRIVER_DEFINE(spaghetti_fake_pwm_driver) = {
	.type_id = "fake_pwm",
	.api_version = SPAGHETTI_MODULE_DRIVER_API_VERSION,
	.required_capabilities = SPAGHETTI_PORT_CAP_DIGITAL_OUTPUT,
	.transport = SPAGHETTI_PORT_TRANSPORT_GPIO,
	.power_requirement = { .declared = false },
	.config_schema = &config_schema,
	.record_schemas = NULL,
	.record_schema_count = 0U,
	.commands = commands,
	.command_count = ARRAY_SIZE(commands),
	.ops = &ops,
};
```

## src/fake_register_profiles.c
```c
/**
 * @file
 * @brief Two Device Profiles sharing the declarative-device driver.
 */

#include <spaghetti/device_profile.h>
#include <spaghetti/port.h>
#include <spaghetti/schema.h>

enum {
	FIELD_VALUE = 1U,
	REG_A = 0x10U,
	REG_B = 0x20U,
};

SPAGHETTI_DEVICE_PROFILE_DEFINE(fake_register_profile_a) = {
	.profile_id = "fake-register-a",
	.version = 1U,
	.transport = SPAGHETTI_PORT_TRANSPORT_I2C,
	.required_capabilities = SPAGHETTI_PORT_CAP_I2C,
	.max_total_time_ms = 1000U,
	.max_transactions = 8U,
	.max_bytes = 32U,
	.sample_ops = {
		{
			.opcode = SPAGHETTI_DEVICE_PROFILE_OP_LOAD_CONST,
			.dst = 0U,
			.imm0 = 1U,
			.imm2 = REG_A,
		},
		{
			.opcode = SPAGHETTI_DEVICE_PROFILE_OP_I2C_WRITE_READ,
			.dst = 1U,
			.src_a = 0U,
			.imm0 = 2U,
			.imm1 = 1U,
			.imm2 = 100U,
		},
		{
			.opcode = SPAGHETTI_DEVICE_PROFILE_OP_EMIT_FIELD,
			.dst = FIELD_VALUE,
			.src_a = 1U,
			.imm0 = 2U,
			.imm1 = 1U,
			.imm3 = 1U,
		},
		{
			.opcode = SPAGHETTI_DEVICE_PROFILE_OP_EMIT_RECORD,
		},
	},
	.sample_count = 4U,
	.sample_schema_id = "spaghetti.fake_reg_a.sample",
	.sample_schema_version = 1U,
	.sample_fields = {
		{
			.field_id = FIELD_VALUE,
			.type = SPAGHETTI_VALUE_INT64,
			.name = "value",
			.unit = "raw",
		},
	},
	.sample_field_count = 1U,
};

SPAGHETTI_DEVICE_PROFILE_DEFINE(fake_register_profile_b) = {
	.profile_id = "fake-register-b",
	.version = 1U,
	.transport = SPAGHETTI_PORT_TRANSPORT_I2C,
	.required_capabilities = SPAGHETTI_PORT_CAP_I2C,
	.max_total_time_ms = 1000U,
	.max_transactions = 8U,
	.max_bytes = 32U,
	.sample_ops = {
		{
			.opcode = SPAGHETTI_DEVICE_PROFILE_OP_LOAD_CONST,
			.dst = 0U,
			.imm0 = 1U,
			.imm2 = REG_B,
		},
		{
			.opcode = SPAGHETTI_DEVICE_PROFILE_OP_I2C_WRITE_READ,
			.dst = 1U,
			.src_a = 0U,
			.imm0 = 2U,
			.imm1 = 1U,
			.imm2 = 100U,
		},
		{
			.opcode = SPAGHETTI_DEVICE_PROFILE_OP_EMIT_FIELD,
			.dst = FIELD_VALUE,
			.src_a = 1U,
			.imm0 = 2U,
			.imm1 = 0U,
			.imm3 = 1U,
		},
		{
			.opcode = SPAGHETTI_DEVICE_PROFILE_OP_EMIT_RECORD,
		},
	},
	.sample_count = 4U,
	.sample_schema_id = "spaghetti.fake_reg_b.sample",
	.sample_schema_version = 1U,
	.sample_fields = {
		{
			.field_id = FIELD_VALUE,
			.type = SPAGHETTI_VALUE_INT64,
			.name = "value",
			.unit = "raw",
		},
	},
	.sample_field_count = 1U,
};
```

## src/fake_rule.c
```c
/**
 * @file
 * @brief Fake rule: observe INT64 field and emit PWM duty command.
 */

#include <errno.h>
#include <stdbool.h>
#include <string.h>

#include <zephyr/sys/util.h>

#include <spaghetti/rule_driver.h>
#include <spaghetti/schema.h>

enum {
	FAKE_RULE_CFG_SOURCE_KEY = 1U,
	FAKE_RULE_CFG_FIELD_ID = 2U,
	FAKE_RULE_CFG_PWM_KEY = 3U,
	FAKE_RULE_CFG_THRESHOLD = 4U,
	FAKE_PWM_CMD_SET_DUTY = 1U,
	FAKE_PWM_CMD_FIELD_DUTY = 1U,
};

struct fake_rule_context {
	bool used;
	spaghetti_module_key_t source_key;
	uint16_t field_id;
	spaghetti_module_key_t pwm_key;
	int64_t threshold;
	uint32_t actions_emitted;
};

static struct fake_rule_context contexts[CONFIG_SPAGHETTI_MAX_RULES];
static uint32_t last_actions_emitted;

static const struct spaghetti_field_descriptor config_fields[] = {
	{
		.field_id = FAKE_RULE_CFG_SOURCE_KEY,
		.type = SPAGHETTI_VALUE_UINT64,
		.flags = SPAGHETTI_FIELD_REQUIRED | SPAGHETTI_FIELD_WRITABLE,
		.unsigned_minimum = 1U,
		.unsigned_maximum = UINT64_MAX,
		.name = "source_key",
		.description = "Observed Module key",
		.unit = "",
	},
	{
		.field_id = FAKE_RULE_CFG_FIELD_ID,
		.type = SPAGHETTI_VALUE_UINT64,
		.flags = SPAGHETTI_FIELD_REQUIRED | SPAGHETTI_FIELD_WRITABLE,
		.unsigned_minimum = 1U,
		.unsigned_maximum = UINT16_MAX,
		.name = "field_id",
		.description = "Observed field",
		.unit = "",
	},
	{
		.field_id = FAKE_RULE_CFG_PWM_KEY,
		.type = SPAGHETTI_VALUE_UINT64,
		.flags = SPAGHETTI_FIELD_REQUIRED | SPAGHETTI_FIELD_WRITABLE,
		.unsigned_minimum = 1U,
		.unsigned_maximum = UINT64_MAX,
		.name = "pwm_key",
		.description = "PWM Module key",
		.unit = "",
	},
	{
		.field_id = FAKE_RULE_CFG_THRESHOLD,
		.type = SPAGHETTI_VALUE_INT64,
		.flags = SPAGHETTI_FIELD_REQUIRED | SPAGHETTI_FIELD_WRITABLE,
		.signed_minimum = INT64_MIN,
		.signed_maximum = INT64_MAX,
		.name = "threshold",
		.description = "Trip threshold",
		.unit = "",
	},
};

static const struct spaghetti_schema_descriptor config_schema = {
	.schema_id = "spaghetti.fake_rule.config",
	.version = 1U,
	.fields = config_fields,
	.field_count = ARRAY_SIZE(config_fields),
};

static int validate_config(const struct spaghetti_property_set *config)
{
	return spaghetti_property_validate(config, &config_schema);
}

static int init_rule(const struct spaghetti_property_set *config,
		     void **out_context)
{
	const struct spaghetti_value *source;
	const struct spaghetti_value *field;
	const struct spaghetti_value *pwm;
	const struct spaghetti_value *threshold;

	if ((config == NULL) || (out_context == NULL)) {
		return -EINVAL;
	}
	source = spaghetti_property_find(config, FAKE_RULE_CFG_SOURCE_KEY);
	field = spaghetti_property_find(config, FAKE_RULE_CFG_FIELD_ID);
	pwm = spaghetti_property_find(config, FAKE_RULE_CFG_PWM_KEY);
	threshold = spaghetti_property_find(config, FAKE_RULE_CFG_THRESHOLD);
	if ((source == NULL) || (field == NULL) || (pwm == NULL) ||
	    (threshold == NULL)) {
		return -EINVAL;
	}
	for (size_t idx = 0U; idx < ARRAY_SIZE(contexts); ++idx) {
		if (!contexts[idx].used) {
			memset(&contexts[idx], 0, sizeof(contexts[idx]));
			contexts[idx].used = true;
			contexts[idx].source_key =
				(spaghetti_module_key_t)source->data.unsigned_integer;
			contexts[idx].field_id =
				(uint16_t)field->data.unsigned_integer;
			contexts[idx].pwm_key =
				(spaghetti_module_key_t)pwm->data.unsigned_integer;
			contexts[idx].threshold =
				threshold->data.signed_integer;
			*out_context = &contexts[idx];
			return 0;
		}
	}
	return -ENOMEM;
}

static int on_record(void *context, const struct spaghetti_record *record,
		     spaghetti_rule_emit_action_cb_t emit,
		     void *emit_user_data)
{
	struct fake_rule_context *ctx = context;
	const struct spaghetti_value *value;
	struct spaghetti_rule_action action;

	if ((ctx == NULL) || (record == NULL) || (emit == NULL)) {
		return -EINVAL;
	}
	if (record->source_key != ctx->source_key) {
		return 0;
	}
	value = spaghetti_property_find(&record->payload.values, ctx->field_id);
	if ((value == NULL) || (value->type != SPAGHETTI_VALUE_INT64) ||
	    (value->data.signed_integer < ctx->threshold)) {
		return 0;
	}

	memset(&action, 0, sizeof(action));
	action.target_key = ctx->pwm_key;
	action.command.command_id = FAKE_PWM_CMD_SET_DUTY;
	action.command.arguments.field_count = 1U;
	action.command.arguments.fields[0] = (struct spaghetti_value){
		.field_id = FAKE_PWM_CMD_FIELD_DUTY,
		.type = SPAGHETTI_VALUE_UINT64,
		.data.unsigned_integer = 500U,
	};
	++ctx->actions_emitted;
	last_actions_emitted = ctx->actions_emitted;
	return emit(&action, emit_user_data);
}

static int deinit_rule(void *context)
{
	struct fake_rule_context *ctx = context;

	if (ctx == NULL) {
		return -EINVAL;
	}
	ctx->used = false;
	return 0;
}

uint32_t fake_rule_last_actions_emitted(void)
{
	return last_actions_emitted;
}

static const struct spaghetti_rule_driver_ops ops = {
	.validate_config = validate_config,
	.init = init_rule,
	.on_record = on_record,
	.deinit = deinit_rule,
};

SPAGHETTI_RULE_DRIVER_DEFINE(spaghetti_fake_rule_driver) = {
	.type_id = "fake_rule",
	.api_version = SPAGHETTI_RULE_DRIVER_API_VERSION,
	.config_schema = &config_schema,
	.ops = &ops,
};
```

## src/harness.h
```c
/**
 * @file
 * @brief Board/service stubs for V1 extension proof (not central subsystems).
 */

#ifndef V1_EXTENSION_HARNESS_H
#define V1_EXTENSION_HARNESS_H

#include <stdbool.h>
#include <stddef.h>
#include <stdint.h>

#include <spaghetti/config.h>
#include <spaghetti/connectivity.h>
#include <spaghetti/mqtt.h>
#include <spaghetti/port.h>
#include <spaghetti/schema.h>
#include <spaghetti/service.h>

struct v1_harness {
	uint32_t storage_writes;
	struct spaghetti_config stored;
	int storage_error;
	size_t runtime_schedule_count;
	size_t runtime_rule_count;
	bool runtime_running;
	struct spaghetti_mqtt_config mqtt;
	enum spaghetti_connectivity_policy connectivity;
	enum spaghetti_service_state service_state;
	bool eeprom_enabled;
	bool analog_enabled;
	uint8_t eeprom_identity[8];
	size_t eeprom_identity_size;
	uint8_t analog_identity[4];
	size_t analog_identity_size;
};

void v1_harness_reset(void);
struct v1_harness *v1_harness_get(void);

void v1_port_reset(void);

#endif /* V1_EXTENSION_HARNESS_H */
```
